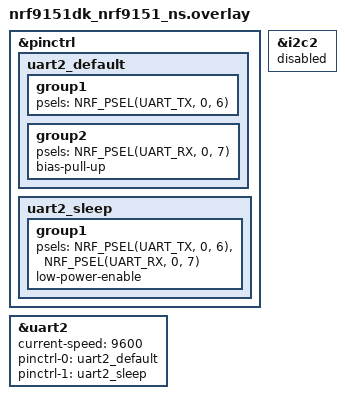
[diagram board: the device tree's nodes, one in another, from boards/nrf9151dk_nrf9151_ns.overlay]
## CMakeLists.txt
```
cmake_minimum_required(VERSION 3.20.0)

find_package(Zephyr REQUIRED HINTS $ENV{ZEPHYR_BASE})
project(mulberry_uart)

target_sources(app PRIVATE
  src/main.c
  src/sdcs.c
)
```

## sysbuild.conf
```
# Sysbuild configuration.
#
# MCUboot is not optional on this target, despite nothing here needing DFU.
#
# The nRF9151-DK ns board pulls in zephyr/dts/vendor/nordic/nrf91xx_partition.dtsi
# via `zephyr,code-partition = &slot0_ns_partition`. That file hardcodes the
# TF-M "with BL2" flash layout:
#
#   0x00000000  BL2 - MCUboot            (64 KB)
#   0x00010000  secure image primary     (256 KB)
#   0x00050000  non-secure image primary (192 KB)
#
# The secure and non-secure images are therefore linked at 0x10000 and 0x50000,
# leaving the 64 KB at the reset vector for a bootloader. Without this option
# sysbuild never builds one, `west flash` writes only the two image regions, and
# the CPU resets into whatever happens to be at 0x0 -- erased flash, or a stale
# image from a previous project. It builds and flashes clean and then hangs
# before reaching TF-M, with a blank console and no other symptom.
#
# Enabling MCUboot fills 0x0 and signs the images so it will accept them.
SB_CONFIG_BOOTLOADER_MCUBOOT=y
```

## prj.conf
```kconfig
# --- Sensor UART (UARTE2 @ 9600 8N1) ---
CONFIG_SERIAL=y
CONFIG_UART_INTERRUPT_DRIVEN=y
CONFIG_RING_BUFFER=y

# --- Console on VCOM0 ---
CONFIG_CONSOLE=y
CONFIG_UART_CONSOLE=y
CONFIG_PRINTK=y
CONFIG_CBPRINTF_FP_SUPPORT=y   # needed for the %f ppm column

# --- Logging ---
CONFIG_LOG=y
CONFIG_LOG_MODE_IMMEDIATE=y
CONFIG_LOG_DEFAULT_LEVEL=3

# --- Sizing ---
CONFIG_MAIN_STACK_SIZE=4096
CONFIG_HEAP_MEM_POOL_SIZE=1024

# --- Modem stays off for milestone 1 ---
# Add CONFIG_NRF_MODEM_LIB=y and the LTE link control options later.
```

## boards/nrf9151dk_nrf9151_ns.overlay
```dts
/*
 * nRF9151-DK overlay: dedicate UARTE2 to the eLichens Mulberry.
 *
 * Pin choice is NOT arbitrary. Verified against the stock board files
 * (zephyr/boards/nordic/nrf9151dk/, v4.2.1):
 *
 *   P0.00  LED1 + pwm0        P0.14  uart0 RTS (A0)
 *   P0.01  LED2               P0.15  uart0 CTS (A1)
 *   P0.02  FREE          (D2) P0.16  uart1 RTS (A2)
 *   P0.03  FREE          (D3) P0.17  uart1 CTS (A3)
 *   P0.04  LED3               P0.18  Button3 (A4)
 *   P0.05  LED4               P0.19  Button4 / PCAL6408A INT (A5)
 *   P0.06  FREE          (D6) P0.20  spi3 CS2
 *   P0.07  FREE          (D7) P0.21  nRF5340 reset (disabled)
 *   P0.08  Button1       (D8) P0.26  uart0 RX  <- console
 *   P0.09  Button2       (D9) P0.27  uart0 TX  <- console
 *   P0.10  spi3 CS      (D10) P0.28  uart1 RX  <- VCOM1
 *   P0.11  spi3 MOSI    (D11) P0.29  uart1 TX  <- VCOM1
 *   P0.12  spi3 MISO    (D12) P0.30  i2c2 SDA (D14)
 *   P0.13  spi3 SCK     (D13) P0.31  i2c2 SCL (D15)
 *
 * Only P0.02, P0.03, P0.06 and P0.07 are unclaimed and brought out to the
 * Arduino digital header. We take D6/D7 (P0.06/P0.07): adjacent pins, no
 * pin contention.
 *
 * There IS instance contention, however. On the nRF91 series UARTE2, SPIM2,
 * SPIS2, TWIM2 and TWIS2 are one peripheral, not five: all at 0x4000A000,
 * all on IRQ 10. The board enables i2c2 (= TWIM2) as `arduino_i2c` on
 * D14/D15, so enabling uart2 without disabling i2c2 puts two Zephyr drivers
 * on the same registers. Different pins, so nothing in the build complains —
 * it just fails on the bench. i2c2 is disabled below.
 */

&pinctrl {
	uart2_default: uart2_default {
		group1 {
			psels = <NRF_PSEL(UART_TX, 0, 6)>;    /* D6 -> sensor RX (pin 4) */
		};
		group2 {
			psels = <NRF_PSEL(UART_RX, 0, 7)>;    /* D7 <- sensor TX (pin 3) */
			bias-pull-up;   /* idle-high if the sensor is unplugged */
		};
	};

	uart2_sleep: uart2_sleep {
		group1 {
			psels = <NRF_PSEL(UART_TX, 0, 6)>,
				<NRF_PSEL(UART_RX, 0, 7)>;
			low-power-enable;
		};
	};
};

/*
 * TWIM2 shares its register block and IRQ with UARTE2 (see header comment).
 * Nothing on this build uses the Arduino I2C header, so give the instance
 * to the sensor UART outright.
 */
&i2c2 {
	status = "disabled";
};

&uart2 {
	status = "okay";
	current-speed = <9600>;   /* Mulberry: 9600 8N1, no parity, no flow ctrl */
	pinctrl-0 = <&uart2_default>;
	pinctrl-1 = <&uart2_sleep>;
	pinctrl-names = "default", "sleep";
};
```

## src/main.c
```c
/*
 * main.c - Mulberry CH4 bring-up on nRF9151-DK
 *
 * Milestone 1: prove the UART link, identify the sensor, then poll
 * GET_DATA_PACK at 1 Hz and print a parsed line to the VCOM console.
 *
 * No modem, no power gating, no NVS. Those come after the link is proven.
 *
 * Redwood Labs Inc.
 */

#include <zephyr/kernel.h>
#include <zephyr/device.h>
#include <zephyr/devicetree.h>
#include <zephyr/drivers/uart.h>
#include <zephyr/logging/log.h>
#include <stdio.h>
#include <string.h>

#include "sdcs.h"

LOG_MODULE_REGISTER(main, LOG_LEVEL_INF);

#define SENSOR_UART_NODE DT_NODELABEL(uart2)
static const struct device *const sensor_uart = DEVICE_DT_GET(SENSOR_UART_NODE);

/* Poll period. Doc s5.4: do not exceed 1 Hz if you care about the current
 * budget. The sensor's own measurement cycle is 500 ms, so 1 Hz never
 * misses a fresh value.
 */
#define POLL_PERIOD_MS 1000

/* Set to 1 once you have a real time source (modem AT+CCLK or GNSS).
 * Leaving it 0 means the ALARM "time not synchronized" bit stays set,
 * which is correct and honest rather than stamping a fictional time.
 */
#define SET_RTC_AT_BOOT 0

/* Set to 1 to run the pin/pinctrl verification instead of talking to the
 * sensor. Jumper D6 to D7 on the Arduino header, flash, and watch the
 * console. This proves the UARTE2 instance, the pinctrl assignment, the
 * physical header location and the 9600 baud setting all at once, with no
 * sensor attached and nothing that can be damaged by a wrong pin.
 *
 * Run this BEFORE the Mulberry is ever connected.
 */
#define LOOPBACK_TEST 0

#if LOOPBACK_TEST
static int run_loopback(void)
{
	static const uint8_t pattern[] = {
		0x7B, 0x59, 0x06, 0x00, 0x00, 0x10, 0xAA, 0x26, 0x7D
	};
	uint8_t got[sizeof(pattern)];
	size_t n = 0;

	printk("\n--- UART2 loopback test ---\n");
	printk("Jumper D6 (P0.06) to D7 (P0.07), then reset.\n");
	printk("Sending a real GET_MODEL_NAME frame at 9600 8N1...\n");

	/* Send one byte, read it back, repeat.
	 *
	 * The obvious version - transmit all nine bytes and then read the
	 * echo - does not work here. uart_poll_out() blocks until each byte
	 * is on the wire, so with TX looped to RX the whole frame arrives
	 * before anything drains it, and the result depends on how much the
	 * UARTE poll-mode RX path happens to buffer rather than on the
	 * wiring. That version dropped byte 8 of 9 reproducibly while every
	 * other byte came back correct.
	 *
	 * Interleaving keeps at most one byte in flight, so a failure here
	 * means the pins, the jumper or the baud rate - which is the only
	 * thing this test is meant to prove.
	 */
	size_t failed_at = sizeof(pattern);

	for (size_t i = 0; i < sizeof(pattern); i++) {
		/* One byte at 9600 8N1 is ~1.04 ms on the wire, plus the
		 * driver's turnaround. 50 ms is far more than enough and
		 * still fails fast when nothing is connected.
		 */
		int64_t deadline = k_uptime_get() + 50;
		bool echoed = false;

		uart_poll_out(sensor_uart, pattern[i]);

		while (k_uptime_get() < deadline) {
			uint8_t b;

			if (uart_poll_in(sensor_uart, &b) == 0) {
				got[n++] = b;
				echoed = true;
				break;
			}
			/* Busy-wait rather than k_sleep(): a tick is 10 ms
			 * by default, which would allow only a handful of
			 * polls inside the deadline.
			 */
			k_busy_wait(100);
		}

		if (!echoed) {
			failed_at = i;
			break;
		}
	}

	printk("sent: ");
	for (size_t i = 0; i < sizeof(pattern); i++) {
		printk("%02X ", pattern[i]);
	}
	printk("\nrecv: ");
	for (size_t i = 0; i < n; i++) {
		printk("%02X ", got[i]);
	}
	printk("(%u/%u bytes)\n", (unsigned)n, (unsigned)sizeof(pattern));

	if (n != sizeof(pattern)) {
		printk("\nRESULT: FAIL - no echo for byte %u (0x%02X).\n",
		       (unsigned)failed_at, pattern[failed_at]);
		printk("  failed on byte 0 -> jumper missing, or wrong "
		       "header pins\n"
		       "  failed later     -> intermittent contact, or "
		       "another peripheral on P0.06/P0.07\n");
		return -EIO;
	}
	if (memcmp(pattern, got, n) != 0) {
		printk("\nRESULT: FAIL - bytes differ. Suspect baud or "
		       "another peripheral driving these pins.\n");
		return -EIO;
	}

	printk("\nRESULT: PASS - UARTE2 is on D6/D7 at 9600 8N1.\n"
	       "Remove the jumper and wire the sensor.\n");
	return 0;
}
#endif /* LOOPBACK_TEST */

static void log_identity(void)
{
	char buf[32];
	uint32_t runtime;

	if (sdcs_get_ascii(SDCS_CMD_GET_MODEL_NAME, buf, sizeof(buf)) == 0) {
		printk("model      : %s\n", buf);
	} else {
		printk("model      : <no response>\n");
	}
	if (sdcs_get_ascii(SDCS_CMD_GET_PROD_NAME, buf, sizeof(buf)) == 0) {
		printk("product    : %s\n", buf);
	}
	if (sdcs_get_ascii(SDCS_CMD_GET_SEN_SN, buf, sizeof(buf)) == 0) {
		printk("serial     : %s\n", buf);
	}
	if (sdcs_get_ascii(SDCS_CMD_GET_FW_VER, buf, sizeof(buf)) == 0) {
		printk("firmware   : %s\n", buf);
	}
	if (sdcs_get_run_time(&runtime) == 0) {
		printk("run time   : %u s (%u h)\n", runtime, runtime / 3600u);
	}
}

static void describe_flags(const struct sdcs_reading *r, char *out, size_t sz)
{
	out[0] = '\0';
	size_t used = 0;

#define APPEND(cond, text)                                                  \
	do {                                                                \
		if ((cond) && used < sz - 1) {                              \
			int _w = snprintk(out + used, sz - used, "%s%s",     \
					  used ? "," : "", text);           \
			if (_w > 0) {                                       \
				used += (size_t)_w;                         \
			}                                                   \
		}                                                           \
	} while (0)

	APPEND(r->status & SDCS_ST_WARMUP, "WARMUP");
	APPEND(r->status & SDCS_ST_IN_CALIBRATION, "IN_CAL");
	APPEND(r->status & SDCS_ST_UNSTABLE_ENV, "UNSTABLE_ENV");
	APPEND(r->alarm & SDCS_AL_OVER_RANGE, "OVER_RANGE");
	APPEND(r->alarm & SDCS_AL_TIME_NOT_SYNC, "TIME_NOT_SYNC");
	APPEND(r->alarm & SDCS_AL_HIGH, "HIGH");
	APPEND(r->alarm & SDCS_AL_LOW, "LOW");
	APPEND(r->alarm & SDCS_AL_OVER_RANGE_HIGH, "OVER_RANGE_HIGH");
	APPEND(r->alarm & SDCS_AL_DRIFT, "DRIFT");
#undef APPEND

	if (out[0] == '\0') {
		strncpy(out, "-", sz);
	}
}

int main(void)
{
	printk("\n=== Redwood Labs / Mulberry CH4 bring-up ===\n");

	if (!device_is_ready(sensor_uart)) {
		printk("FATAL: sensor UART not ready\n");
		return -ENODEV;
	}

#if LOOPBACK_TEST
	/* Runs before sdcs_init() on purpose: the SDCS client enables
	 * interrupt-driven RX, which would consume the bytes that
	 * uart_poll_in() is waiting for.
	 */
	while (true) {
		(void)run_loopback();
		k_sleep(K_SECONDS(5));
	}
#endif

	int rc = sdcs_init(sensor_uart);

	if (rc) {
		printk("FATAL: sdcs_init failed (%d)\n", rc);
		return rc;
	}

	/* Self test of the CRC before we blame the wiring for anything. */
	uint16_t check = sdcs_crc16((const uint8_t *)"123456789", 9);

	printk("CRC-16/BUYPASS self test: %04x (expect FEE8) %s\n",
	       check, (check == 0xFEE8u) ? "OK" : "FAIL");

	/* Doc s5.1: comms ready within 100 ms of power-on, first gas value
	 * after 30 s of warm-up. Give the sensor a moment if we booted together.
	 */
	k_sleep(K_MSEC(500));

	printk("\n--- identity ---\n");
	log_identity();

#if SET_RTC_AT_BOOT
	printk("\n--- RTC sync ---\n");
	if (sdcs_write_protect(false) == 0) {
		/* Replace with a real time source before trusting this. */
		if (sdcs_set_rtc(2026, 8, 14, 12, 0, 0) == 0) {
			printk("RTC set\n");
		}
		sdcs_write_protect(true);
	}
#endif

	printk("\n--- polling at %d ms ---\n", POLL_PERIOD_MS);
	printk("  ppm     act    ref   T(C)  flags\n");

	uint32_t consecutive_failures = 0;

	while (true) {
		struct sdcs_reading r;
		char flags[128];

		rc = sdcs_get_data_pack(SDCS_DP_MULBERRY_ALL, &r);
		if (rc < 0) {
			consecutive_failures++;
			printk("read failed (%d), %u in a row\n",
			       rc, consecutive_failures);
			if (consecutive_failures >= 3) {
				/* Doc s5.5: 3 in a row means power-cycle the
				 * sensor. Soft reset will not help.
				 */
				printk("sensor considered offline - "
				       "hard reset required\n");
			}
			k_sleep(K_MSEC(POLL_PERIOD_MS));
			continue;
		}
		consecutive_failures = 0;

		describe_flags(&r, flags, sizeof(flags));

		printk("%8.2f %6u %6u %5d  %s",
		       (double)r.gas_ppm_x100 / 100.0,
		       r.raw_active, r.raw_reference,
		       r.temp_sensor_error ? -999 : r.temp_c,
		       flags);

		if (r.n_errors) {
			printk("  ERR[");
			for (uint8_t e = 0; e < r.n_errors; e++) {
				printk("%s%u", e ? "," : "", r.errors[e]);
			}
			printk("]");
		}
		printk("\n");

		k_sleep(K_MSEC(POLL_PERIOD_MS));
	}

	return 0;
}
```

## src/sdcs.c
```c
/*
 * sdcs.c - eLichens SDCS client for Zephyr / nRF Connect SDK
 * Redwood Labs Inc.
 */

#include "sdcs.h"

#include <zephyr/kernel.h>
#include <zephyr/drivers/uart.h>
#include <zephyr/sys/ring_buffer.h>
#include <zephyr/logging/log.h>
#include <string.h>

LOG_MODULE_REGISTER(sdcs, LOG_LEVEL_INF);

/* Protocol timing (rev2.5 s2.3): response within 250 ms, 3 timeouts = offline.
 * 400 ms gives margin for the sensor's 500 ms measure cycle boundary.
 */
#define SDCS_RESP_TIMEOUT_MS  400
#define SDCS_BYTE_GAP_MS      50
#define SDCS_RETRIES          2

#define RX_RING_SIZE 256

/* Bring-up diagnostic: dump every well-formed response frame as raw hex
 * before anything parses it, and call out the gas field with the offset it
 * was read from. Set to 0 for normal operation - at 1 Hz with a full
 * Mulberry data pack this roughly triples console traffic.
 */
#define SDCS_LOG_RAW_FRAMES 0

static const struct device *uart;
static uint8_t rx_ring_buf[RX_RING_SIZE];
static struct ring_buf rx_ring;
static K_SEM_DEFINE(rx_sem, 0, 1);
static K_MUTEX_DEFINE(bus_lock);
static uint16_t tx_index;

uint16_t sdcs_crc16(const uint8_t *buf, size_t len)
{
	uint16_t crc = 0x0000;

	for (size_t i = 0; i < len; i++) {
		crc ^= (uint16_t)buf[i] << 8;
		for (int b = 0; b < 8; b++) {
			crc = (crc & 0x8000u) ? (uint16_t)((crc << 1) ^ 0x8005u)
					      : (uint16_t)(crc << 1);
		}
	}
	return crc;
}

static void uart_isr(const struct device *dev, void *user_data)
{
	ARG_UNUSED(user_data);
	uint8_t byte;

	if (!uart_irq_update(dev)) {
		return;
	}

	while (uart_irq_rx_ready(dev)) {
		if (uart_fifo_read(dev, &byte, 1) != 1) {
			break;
		}
		if (ring_buf_put(&rx_ring, &byte, 1) != 1) {
			LOG_WRN("rx ring overflow, byte dropped");
		}
		k_sem_give(&rx_sem);
	}
}

int sdcs_init(const struct device *uart_dev)
{
	if (!device_is_ready(uart_dev)) {
		return -ENODEV;
	}

	uart = uart_dev;
	ring_buf_init(&rx_ring, sizeof(rx_ring_buf), rx_ring_buf);

	int rc = uart_irq_callback_user_data_set(uart, uart_isr, NULL);

	if (rc != 0) {
		return rc;
	}
	uart_irq_rx_enable(uart);
	return 0;
}

static void rx_flush(void)
{
	ring_buf_reset(&rx_ring);
	k_sem_reset(&rx_sem);
}

/* Blocking read of exactly one byte with a deadline. */
static int rx_byte(uint8_t *out, k_timepoint_t deadline)
{
	while (true) {
		if (ring_buf_get(&rx_ring, out, 1) == 1) {
			return 0;
		}
		if (sys_timepoint_expired(deadline)) {
			return -ETIMEDOUT;
		}
		(void)k_sem_take(&rx_sem, sys_timepoint_timeout(deadline));
	}
}

static void tx_frame(const uint8_t *frame, size_t len)
{
	for (size_t i = 0; i < len; i++) {
		uart_poll_out(uart, frame[i]);
	}
}

/* Read one well-formed frame. Returns total frame length in buf, or negative. */
static int rx_frame(uint8_t *buf, size_t buf_max, k_timepoint_t deadline)
{
	uint8_t b;
	int rc;

	/* Hunt for SOP. Anything before it is line noise or a stale tail. */
	do {
		rc = rx_byte(&b, deadline);
		if (rc) {
			return rc;
		}
	} while (b != SDCS_SOP);

	if (buf_max < 4) {
		return -ENOSPC;
	}
	buf[0] = b;

	rc = rx_byte(&buf[1], deadline);   /* Ver */
	if (rc) {
		return rc;
	}
	rc = rx_byte(&buf[2], deadline);   /* Len */
	if (rc) {
		return rc;
	}

	if (buf[1] != SDCS_VER) {
		LOG_WRN("bad version 0x%02x", buf[1]);
		return -EPROTO;
	}

	size_t total = (size_t)buf[2] + 3u;   /* Len counts everything after Len */

	if (total > buf_max || total < 6u) {
		LOG_WRN("bad length field 0x%02x", buf[2]);
		return -EPROTO;
	}

	for (size_t i = 3; i < total; i++) {
		rc = rx_byte(&buf[i], deadline);
		if (rc) {
			return rc;
		}
	}

	if (buf[total - 1] != SDCS_EOP) {
		LOG_WRN("bad EOP 0x%02x", buf[total - 1]);
		return -EPROTO;
	}

	uint16_t calc = sdcs_crc16(buf, total - 3);
	uint16_t got  = ((uint16_t)buf[total - 3] << 8) | buf[total - 2];

	if (calc != got) {
		LOG_WRN("CRC mismatch: calc %04x got %04x", calc, got);
		return -EBADMSG;
	}

	return (int)total;
}

int sdcs_transact(uint8_t cmd, const uint8_t *req, size_t req_len,
		  uint8_t *resp, size_t resp_max, uint8_t *slave_err)
{
	uint8_t frame[6 + SDCS_MAX_DATA + 3];
	uint8_t rbuf[6 + SDCS_MAX_DATA + 3];
	int rc = -EIO;

	if (uart == NULL) {
		return -ENODEV;
	}
	if (req_len > SDCS_MAX_DATA) {
		return -EINVAL;
	}
	if (slave_err) {
		*slave_err = 0;
	}

	k_mutex_lock(&bus_lock, K_FOREVER);

	for (int attempt = 0; attempt <= SDCS_RETRIES; attempt++) {
		size_t n = 0;
		size_t total = 6u + req_len + 3u;

		frame[n++] = SDCS_SOP;
		frame[n++] = SDCS_VER;
		frame[n++] = (uint8_t)(total - 3u);
		frame[n++] = (uint8_t)(tx_index >> 8);
		frame[n++] = (uint8_t)(tx_index & 0xFFu);
		frame[n++] = cmd;
		if (req_len) {
			memcpy(&frame[n], req, req_len);
			n += req_len;
		}

		uint16_t crc = sdcs_crc16(frame, n);

		frame[n++] = (uint8_t)(crc >> 8);
		frame[n++] = (uint8_t)(crc & 0xFFu);
		frame[n++] = SDCS_EOP;

		rx_flush();
		tx_frame(frame, n);

		k_timepoint_t deadline = sys_timepoint_calc(K_MSEC(SDCS_RESP_TIMEOUT_MS));
		int flen = rx_frame(rbuf, sizeof(rbuf), deadline);

		if (flen == -ETIMEDOUT) {
			LOG_WRN("cmd 0x%02x timeout (attempt %d)", cmd, attempt + 1);
			rc = -ETIMEDOUT;
			continue;
		}
		if (flen < 0) {
			rc = flen;
			continue;   /* framing/CRC error - a resend is reasonable */
		}

#if SDCS_LOG_RAW_FRAMES
		/* Whole frame, SOP through EOP, exactly as it came off the
		 * wire. Dumped here so field offsets can be checked by hand
		 * against the Pi reference without trusting the parser.
		 */
		printk("rx cmd 0x%02x (%d B): ", cmd, flen);
		for (int k = 0; k < flen; k++) {
			printk("%02X ", rbuf[k]);
		}
		printk("\n");
#endif

		tx_index++;

		uint8_t rcmd = rbuf[5];
		size_t  dlen = (size_t)flen - 9u;   /* SOP,Ver,Len,Idx*2,Cmd,CRC*2,EOP */

		if (rcmd == SDCS_CMD_ERROR_SLAVE) {
			uint8_t code = (dlen >= 1) ? rbuf[6] : 0;

			if (slave_err) {
				*slave_err = code;
			}
			/* Doc s2.5: do not retransmit, the answer will not change. */
			LOG_WRN("cmd 0x%02x -> error packet 0x%02x", cmd, code);
			rc = -EPROTO;
			break;
		}

		if (rcmd != cmd) {
			LOG_WRN("cmd echo mismatch: sent 0x%02x got 0x%02x", cmd, rcmd);
			rc = -EPROTO;
			continue;
		}

		if (dlen > resp_max) {
			rc = -ENOSPC;
			break;
		}
		if (dlen && resp) {
			memcpy(resp, &rbuf[6], dlen);
		}
		rc = (int)dlen;
		break;
	}

	k_mutex_unlock(&bus_lock);
	return rc;
}

int sdcs_get_ascii(uint8_t cmd, char *out, size_t out_sz)
{
	uint8_t data[SDCS_MAX_DATA];
	int n = sdcs_transact(cmd, NULL, 0, data, sizeof(data), NULL);

	if (n < 0) {
		return n;
	}

	size_t copy = MIN((size_t)n, out_sz - 1);

	memcpy(out, data, copy);
	out[copy] = '\0';

	/* Trim any trailing non-printables; some fields are NUL padded. */
	for (size_t i = 0; i < copy; i++) {
		if (out[i] < 0x20 || out[i] > 0x7E) {
			out[i] = '\0';
			break;
		}
	}
	return 0;
}

int sdcs_get_run_time(uint32_t *seconds)
{
	uint8_t d[8];
	int n = sdcs_transact(SDCS_CMD_GET_RUN_TIME, NULL, 0, d, sizeof(d), NULL);

	if (n < 4) {
		return (n < 0) ? n : -EPROTO;
	}
	*seconds = ((uint32_t)d[0] << 24) | ((uint32_t)d[1] << 16) |
		   ((uint32_t)d[2] << 8) | d[3];
	return 0;
}

int sdcs_get_data_pack(uint16_t bitmap, struct sdcs_reading *out)
{
	uint8_t req[3] = { 0x00, (uint8_t)(bitmap >> 8), (uint8_t)(bitmap & 0xFFu) };
	uint8_t d[SDCS_MAX_DATA];

	int n = sdcs_transact(SDCS_CMD_GET_DATA_PACK, req, sizeof(req),
			      d, sizeof(d), NULL);
	if (n < 0) {
		return n;
	}

	memset(out, 0, sizeof(*out));
	size_t i = 0;

	/* Fields arrive in bit order B0..B5, only for bits that were requested. */
	if (bitmap & SDCS_DP_STATUS) {
		if (i >= (size_t)n) {
			return -EPROTO;
		}
		out->status = d[i++];
		out->have_status = true;
	}
	if (bitmap & SDCS_DP_ALARM) {
		if (i >= (size_t)n) {
			return -EPROTO;
		}
		out->alarm = d[i++];
		out->have_alarm = true;
	}
	if (bitmap & SDCS_DP_ERROR) {
		if (i >= (size_t)n) {
			return -EPROTO;
		}
		out->n_errors = d[i++];
		if (out->n_errors > SDCS_MAX_ERRORS ||
		    i + out->n_errors > (size_t)n) {
			return -EPROTO;
		}
		for (uint8_t e = 0; e < out->n_errors; e++) {
			out->errors[e] = d[i++];
		}
		out->have_errors = true;
	}
	if (bitmap & SDCS_DP_GAS) {
		if (i + 4 > (size_t)n) {
			return -EPROTO;
		}
		out->gas_ppm_x100 = (int32_t)(((uint32_t)d[i] << 24) |
					      ((uint32_t)d[i + 1] << 16) |
					      ((uint32_t)d[i + 2] << 8) |
					      d[i + 3]);
#if SDCS_LOG_RAW_FRAMES
		printk("  gas @payload[%u]: %02X %02X %02X %02X -> %d ppm*100\n",
		       (unsigned)i, d[i], d[i + 1], d[i + 2], d[i + 3],
		       (int)out->gas_ppm_x100);
#endif
		i += 4;
		out->have_gas = true;
	}
	if (bitmap & SDCS_DP_RAW_COUNTS) {
		if (i >= (size_t)n) {
			return -EPROTO;
		}
		uint8_t nch = d[i++];

		if (nch != 2 || i + 4 > (size_t)n) {
			return -EPROTO;
		}
		out->raw_active    = ((uint16_t)d[i] << 8) | d[i + 1];
		out->raw_reference = ((uint16_t)d[i + 2] << 8) | d[i + 3];
		i += 4;
		out->have_raw = true;
	}
	if (bitmap & SDCS_DP_TEMPERATURE) {
		if (i >= (size_t)n) {
			return -EPROTO;
		}
		uint8_t t = d[i++];

		if (t == 0xFF) {
			out->temp_sensor_error = true;
		} else {
			out->temp_c = (int16_t)t - 127;
		}
		out->have_temp = true;
	}

	return 0;
}

int sdcs_write_protect(bool enable)
{
	uint8_t req = enable ? 0x01u : 0x00u;
	uint8_t err = 0;
	int rc = sdcs_transact(SDCS_CMD_WRITE_PROTECT, &req, 1, NULL, 0, &err);

	return (rc < 0) ? rc : 0;
}

int sdcs_set_rtc(uint16_t year, uint8_t month, uint8_t day,
		 uint8_t hour, uint8_t minute, uint8_t second)
{
	if (year < 2000 || year > 2099) {
		return -EINVAL;
	}

	uint8_t req[6] = {
		(uint8_t)(year - 2000), month, day, hour, minute, second
	};
	uint8_t err = 0;

	int rc = sdcs_transact(SDCS_CMD_SET_SEN_RTC, req, sizeof(req), NULL, 0, &err);

	if (rc == -EPROTO && err == SDCS_ERR_FAIL_NOWRITE) {
		LOG_ERR("SET_SEN_RTC refused: write protect is on");
	}

	/* Sensor stalls its UART while committing to NVM. Doc s4.4: wait 1 s. */
	k_sleep(K_MSEC(1100));

	return (rc < 0) ? rc : 0;
}
```

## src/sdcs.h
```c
/*
 * sdcs.h - eLichens Safety Device Communication Standard (SDCS) client
 *
 * Target sensor: eLichens Mulberry (MULBERRY-13 / MUL13442-Safety-CH4-5-vol)
 * Protocol ref:  eLichens sensors communication protocol rev2.5
 * Frame:         SOP(1) Ver(1) Len(1) Index(2) Cmd(1) Data(0..n) CRC(2) EOP(1)
 *                Len = total_frame_len - 3
 *                CRC = CRC-16/BUYPASS over SOP..Data, transmitted MSB first
 *
 * Redwood Labs Inc.
 */

#ifndef SDCS_H_
#define SDCS_H_

#include <stdint.h>
#include <stdbool.h>
#include <stddef.h>
#include <zephyr/device.h>

#define SDCS_SOP                0x7Bu
#define SDCS_VER                0x59u
#define SDCS_EOP                0x7Du
#define SDCS_CMD_ERROR_SLAVE    0x71u

/* Commands (rev2.5 section 3) */
#define SDCS_CMD_GET_MODEL_NAME     0x10u
#define SDCS_CMD_GET_PROD_NAME      0x11u
#define SDCS_CMD_GET_FW_VER         0x12u
#define SDCS_CMD_GET_SEN_SN         0x13u
#define SDCS_CMD_GET_RUN_TIME       0x14u
#define SDCS_CMD_GET_APP_MODE       0x17u
#define SDCS_CMD_GET_SEN_NAME       0x35u
#define SDCS_CMD_GET_DATA_PACK      0x30u
#define SDCS_CMD_GET_SEN_DATA_FMT   0x31u
#define SDCS_CMD_GET_SEN_PARA       0x33u
#define SDCS_CMD_GET_SEN_PROD_DATE  0x37u
#define SDCS_CMD_GET_SEN_RTC        0x38u
#define SDCS_CMD_SET_SEN_PARA       0x80u
#define SDCS_CMD_SET_SEN_RTC        0x82u
#define SDCS_CMD_WRITE_PROTECT      0xA0u

/* GET_DATA_PACK request bitmap (DH[1]=high, DH[2]=low) */
#define SDCS_DP_STATUS      (1u << 0)
#define SDCS_DP_ALARM       (1u << 1)
#define SDCS_DP_ERROR       (1u << 2)
#define SDCS_DP_GAS         (1u << 3)
#define SDCS_DP_RAW_COUNTS  (1u << 4)
#define SDCS_DP_TEMPERATURE (1u << 5)
#define SDCS_DP_HUMIDITY    (1u << 6)   /* Bilberry only - do NOT set for Mulberry */
#define SDCS_DP_MULBERRY_ALL (SDCS_DP_STATUS | SDCS_DP_ALARM | SDCS_DP_ERROR | \
			      SDCS_DP_GAS | SDCS_DP_RAW_COUNTS | SDCS_DP_TEMPERATURE)

/* Sensor status byte */
#define SDCS_ST_WARMUP          (1u << 1)
#define SDCS_ST_IN_CALIBRATION  (1u << 3)
#define SDCS_ST_UNSTABLE_ENV    (1u << 4)

/* Sensor alarm byte */
#define SDCS_AL_OVER_RANGE      (1u << 0)
#define SDCS_AL_TIME_NOT_SYNC   (1u << 2)
#define SDCS_AL_HIGH            (1u << 3)
#define SDCS_AL_LOW             (1u << 4)
#define SDCS_AL_OVER_RANGE_HIGH (1u << 5)
#define SDCS_AL_DRIFT           (1u << 7)

/* Protocol error codes (Appendix I), returned as -SDCS_ESLAVE_BASE - code */
#define SDCS_ERR_FAIL_UNKNOWN       0x31u
#define SDCS_ERR_FAIL_INVALIDCMD    0x32u
#define SDCS_ERR_FAIL_DATASIZE      0x33u
#define SDCS_ERR_FAIL_INVALIDVALUE  0x34u
#define SDCS_ERR_FAIL_NOWRITE       0x39u
#define SDCS_ERR_FAIL_OPERATION     0x3Fu

#define SDCS_MAX_DATA 128
#define SDCS_MAX_ERRORS 10

struct sdcs_reading {
	bool     have_status;
	uint8_t  status;
	bool     have_alarm;
	uint8_t  alarm;
	bool     have_errors;
	uint8_t  n_errors;
	uint8_t  errors[SDCS_MAX_ERRORS];
	bool     have_gas;
	int32_t  gas_ppm_x100;   /* ppm * 100, signed */
	bool     have_raw;
	uint16_t raw_active;
	uint16_t raw_reference;
	bool     have_temp;
	bool     temp_sensor_error;  /* raw byte was 0xFF */
	int16_t  temp_c;             /* raw - 127 */
};

/* Bind the client to an already-ready UART device (9600 8N1). */
int sdcs_init(const struct device *uart_dev);

/* Raw request/response. Returns response data length, or negative errno.
 * A slave Error Packet returns -EPROTO and stores the code in *slave_err.
 * Pass slave_err = NULL if you do not care.
 */
int sdcs_transact(uint8_t cmd, const uint8_t *req, size_t req_len,
		  uint8_t *resp, size_t resp_max, uint8_t *slave_err);

/* ASCII getters (GET_MODEL_NAME, GET_PROD_NAME, GET_FW_VER, GET_SEN_SN). */
int sdcs_get_ascii(uint8_t cmd, char *out, size_t out_sz);

/* GET_RUN_TIME - total powered seconds, MSB first. */
int sdcs_get_run_time(uint32_t *seconds);

/* GET_DATA_PACK. bitmap is any OR of SDCS_DP_*. */
int sdcs_get_data_pack(uint16_t bitmap, struct sdcs_reading *out);

/* WRITE_PROTECT: enable=false unlocks for ~300 s, then it re-locks itself. */
int sdcs_write_protect(bool enable);

/* SET_SEN_RTC. Must be called after every sensor power-on or the
 * "time not synchronized" alarm bit stays set. Requires write protect off.
 * year is the full year (e.g. 2026); the wire format carries year-2000.
 */
int sdcs_set_rtc(uint16_t year, uint8_t month, uint8_t day,
		 uint8_t hour, uint8_t minute, uint8_t second);

/* CRC-16/BUYPASS: poly 0x8005, init 0x0000, no reflection, xorout 0x0000.
 * Check value for "123456789" is 0xFEE8.
 */
uint16_t sdcs_crc16(const uint8_t *buf, size_t len);

#endif /* SDCS_H_ */
```
